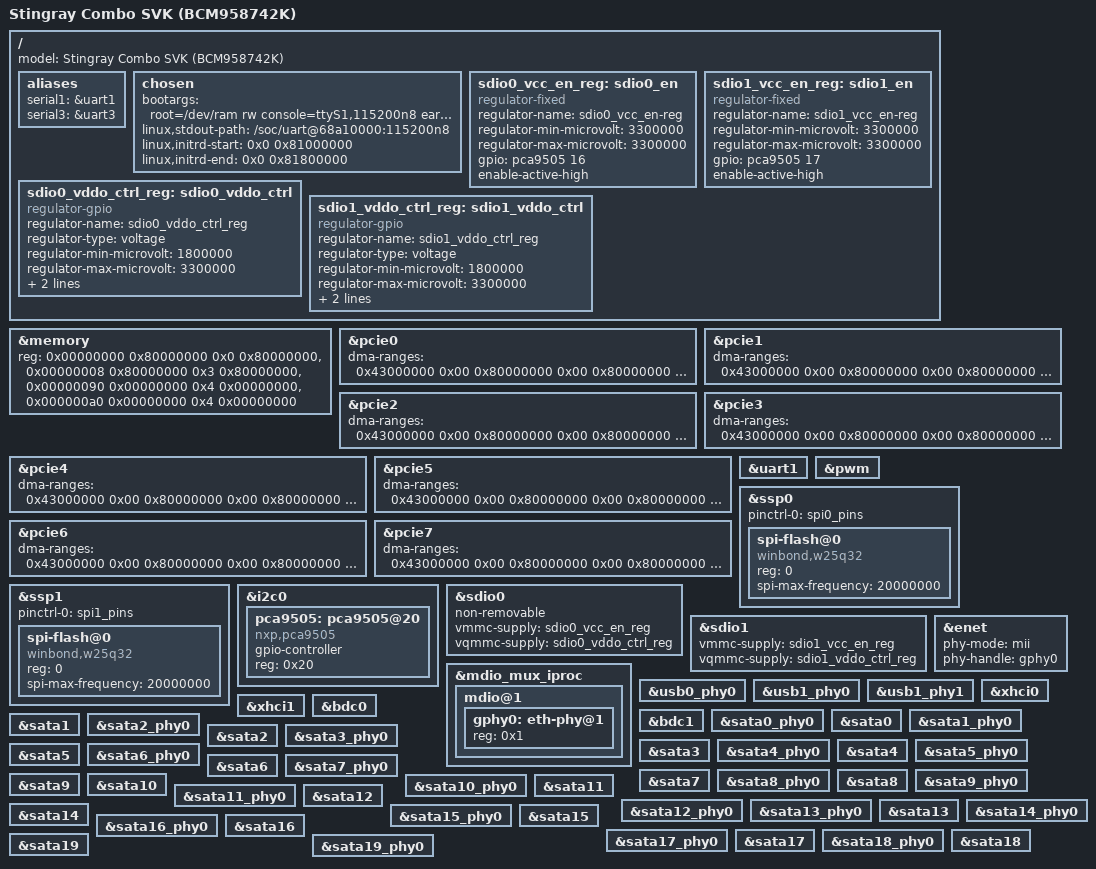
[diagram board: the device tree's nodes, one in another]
/*
 *  BSD LICENSE
 *
 *  Copyright(c) 2016 Broadcom.  All rights reserved.
 *
 *  Redistribution and use in source and binary forms, with or without
 *  modification, are permitted provided that the following conditions
 *  are met:
 *
 *    * Redistributions of source code must retain the above copyright
 *      notice, this list of conditions and the following disclaimer.
 *    * Redistributions in binary form must reproduce the above copyright
 *      notice, this list of conditions and the following disclaimer in
 *      the documentation and/or other materials provided with the
 *      distribution.
 *    * Neither the name of Broadcom Corporation nor the names of its
 *      contributors may be used to endorse or promote products derived
 *      from this software without specific prior written permission.
 *
 *  THIS SOFTWARE IS PROVIDED BY THE COPYRIGHT HOLDERS AND CONTRIBUTORS
 *  "AS IS" AND ANY EXPRESS OR IMPLIED WARRANTIES, INCLUDING, BUT NOT
 *  LIMITED TO, THE IMPLIED WARRANTIES OF MERCHANTABILITY AND FITNESS FOR
 *  A PARTICULAR PURPOSE ARE DISCLAIMED. IN NO EVENT SHALL THE COPYRIGHT
 *  OWNER OR CONTRIBUTORS BE LIABLE FOR ANY DIRECT, INDIRECT, INCIDENTAL,
 *  SPECIAL, EXEMPLARY, OR CONSEQUENTIAL DAMAGES (INCLUDING, BUT NOT
 *  LIMITED TO, PROCUREMENT OF SUBSTITUTE GOODS OR SERVICES; LOSS OF USE,
 *  DATA, OR PROFITS; OR BUSINESS INTERRUPTION) HOWEVER CAUSED AND ON ANY
 *  THEORY OF LIABILITY, WHETHER IN CONTRACT, STRICT LIABILITY, OR TORT
 *  (INCLUDING NEGLIGENCE OR OTHERWISE) ARISING IN ANY WAY OUT OF THE USE
 * OF THIS SOFTWARE, EVEN IF ADVISED OF THE POSSIBILITY OF SUCH DAMAGE.
 */

/dts-v1/;

/* HACK: Reserve bl31 location
 * The memreserve entry for bl31 is supposed to
 * be updated in DTB by bootloader before handing
 * over DTB to Linux kernel. This is so because
 * only firmware (or bootloader) know the correct
 * location of bl31 and bl31 location in DDR can
 * also change in-future.
 */
/memreserve/ 0x8f000000 0x00100000;

#include "stingray.dtsi"
#include <dt-bindings/gpio/gpio.h>

/ {
	model = "Stingray Combo SVK (BCM958742K)";

	aliases {
		serial1 = &uart1;
		serial3 = &uart3;
	};

	chosen { /* HACK: hard-code kernel args and initrd location */
		bootargs = "root=/dev/ram rw console=ttyS1,115200n8 \
			    earlycon=uart8250,mmio32,0x68a10000 cma=64M";
		linux,stdout-path = "/soc/uart@68a10000:115200n8";
		linux,initrd-start = <0x0 0x81000000>;
		linux,initrd-end = <0x0 0x81800000>;
	};

	sdio0_vcc_en_reg: sdio0_en {
		compatible = "regulator-fixed";
		regulator-name = "sdio0_vcc_en-reg";
		regulator-min-microvolt = <3300000>;
		regulator-max-microvolt = <3300000>;
		gpio = <&pca9505 16 0>;
		enable-active-high;
	};

	sdio1_vcc_en_reg: sdio1_en {
		compatible = "regulator-fixed";
		regulator-name = "sdio1_vcc_en-reg";
		regulator-min-microvolt = <3300000>;
		regulator-max-microvolt = <3300000>;
		gpio = <&pca9505 17 0>;
		enable-active-high;
	};

	sdio0_vddo_ctrl_reg: sdio0_vddo_ctrl {
		compatible = "regulator-gpio";
		regulator-name = "sdio0_vddo_ctrl_reg";
		regulator-type = "voltage";
		regulator-min-microvolt = <1800000>;
		regulator-max-microvolt = <3300000>;
		gpios = <&pca9505 18 0>;
		states = <3300000 0x0
			  1800000 0x1>;
	};

	sdio1_vddo_ctrl_reg: sdio1_vddo_ctrl {
		compatible = "regulator-gpio";
		regulator-name = "sdio1_vddo_ctrl_reg";
		regulator-type = "voltage";
		regulator-min-microvolt = <1800000>;
		regulator-max-microvolt = <3300000>;
		gpios = <&pca9505 19 0>;
		states = <3300000 0x0
			  1800000 0x1>;
	};
};

&memory {
	reg = <0x00000000 0x80000000 0x0 0x80000000>, /* 2G @ 2G */
	      <0x00000008 0x80000000 0x3 0x80000000>, /* 14G @ 34G */
	      <0x00000090 0x00000000 0x4 0x00000000>, /* 16G @ 576G */
	      <0x000000a0 0x00000000 0x4 0x00000000>; /* 16G @ 640G */
};

&pcie0 {
	dma-ranges = <0x43000000 0x00 0x80000000 0x00 0x80000000 0x00 0x80000000
		      0x43000000 0x08 0x00000000 0x08 0x00000000 0x08 0x00000000
		      0x43000000 0x80 0x00000000 0x80 0x00000000 0x40 0x00000000>;

	status = "ok";
};

&pcie1 {
	dma-ranges = <0x43000000 0x00 0x80000000 0x00 0x80000000 0x00 0x80000000
		      0x43000000 0x08 0x00000000 0x08 0x00000000 0x08 0x00000000
		      0x43000000 0x80 0x00000000 0x80 0x00000000 0x40 0x00000000>;

	status = "ok";
};

&pcie2 {
	dma-ranges = <0x43000000 0x00 0x80000000 0x00 0x80000000 0x00 0x80000000
		      0x43000000 0x08 0x00000000 0x08 0x00000000 0x08 0x00000000
		      0x43000000 0x80 0x00000000 0x80 0x00000000 0x40 0x00000000>;

	status = "ok";
};

&pcie3 {
	dma-ranges = <0x43000000 0x00 0x80000000 0x00 0x80000000 0x00 0x80000000
		      0x43000000 0x08 0x00000000 0x08 0x00000000 0x08 0x00000000
		      0x43000000 0x80 0x00000000 0x80 0x00000000 0x40 0x00000000>;

	status = "ok";
};

&pcie4 {
	dma-ranges = <0x43000000 0x00 0x80000000 0x00 0x80000000 0x00 0x80000000
		      0x43000000 0x08 0x00000000 0x08 0x00000000 0x08 0x00000000
		      0x43000000 0x80 0x00000000 0x80 0x00000000 0x40 0x00000000>;

	status = "ok";
};

&pcie5 {
	dma-ranges = <0x43000000 0x00 0x80000000 0x00 0x80000000 0x00 0x80000000
		      0x43000000 0x08 0x00000000 0x08 0x00000000 0x08 0x00000000
		      0x43000000 0x80 0x00000000 0x80 0x00000000 0x40 0x00000000>;

	status = "ok";
};

&pcie6 {
	dma-ranges = <0x43000000 0x00 0x80000000 0x00 0x80000000 0x00 0x80000000
		      0x43000000 0x08 0x00000000 0x08 0x00000000 0x08 0x00000000
		      0x43000000 0x80 0x00000000 0x80 0x00000000 0x40 0x00000000>;

	status = "ok";
};

&pcie7 {
	dma-ranges = <0x43000000 0x00 0x80000000 0x00 0x80000000 0x00 0x80000000
		      0x43000000 0x08 0x00000000 0x08 0x00000000 0x08 0x00000000
		      0x43000000 0x80 0x00000000 0x80 0x00000000 0x40 0x00000000>;

	status = "ok";
};

&uart1 {
	status = "ok";
};

&pwm {
	status = "ok";
};

&ssp0 {
	status = "ok";
	pinctrl-0 = <&spi0_pins>;
	spi-flash@0 {
		compatible = "winbond,w25q32";
		reg = <0>;
		spi-max-frequency = <20000000>;
	};
};

&ssp1 {
	status = "ok";
	pinctrl-0 = <&spi1_pins>;
	spi-flash@0 {
		compatible = "winbond,w25q32";
		reg = <0>;
		spi-max-frequency = <20000000>;
	};
};

&i2c0 {
	status = "ok";
	pca9505: pca9505@20 {
		compatible = "nxp,pca9505";
		gpio-controller;
		#gpio-cells = <2>;
		reg = <0x20>;
	};
};

&sdio0 {
	non-removable;
	status = "ok";
	vmmc-supply = <&sdio0_vcc_en_reg>;
	vqmmc-supply = <&sdio0_vddo_ctrl_reg>;
};

&sdio1 {
	status = "ok";
	vmmc-supply = <&sdio1_vcc_en_reg>;
	vqmmc-supply = <&sdio1_vddo_ctrl_reg>;
};

&mdio_mux_iproc {
	mdio@1 {
		gphy0: eth-phy@1 {
			reg = <0x1>;
		};
	};
};

&enet {
	phy-mode = "mii";
	phy-handle = <&gphy0>;
};

&usb0_phy0 {
	status = "ok";
};

&usb1_phy0 {
	status = "ok";
};

&usb1_phy1 {
	status = "ok";
};

&xhci0 {
	status = "ok";
};

&xhci1 {
	status = "ok";
};

&bdc0 {
	status = "ok";
};

&bdc1 {
	status = "ok";
};

&sata0_phy0 {
	status = "ok";
};

&sata0 {
	status = "ok";
};

&sata1_phy0 {
	status = "ok";
};

&sata1 {
	status = "ok";
};

&sata2_phy0 {
	status = "ok";
};

&sata2 {
	status = "ok";
};

&sata3_phy0 {
	status = "ok";
};

&sata3 {
	status = "ok";
};

&sata4_phy0 {
	status = "ok";
};

&sata4 {
	status = "ok";
};

&sata5_phy0 {
	status = "ok";
};

&sata5 {
	status = "ok";
};

&sata6_phy0 {
	status = "ok";
};

&sata6 {
	status = "ok";
};

&sata7_phy0 {
	status = "ok";
};

&sata7 {
	status = "ok";
};

&sata8_phy0 {
	status = "ok";
};

&sata8 {
	status = "ok";
};

&sata9_phy0 {
	status = "ok";
};

&sata9 {
	status = "ok";
};

&sata10_phy0 {
	status = "ok";
};

&sata10 {
	status = "ok";
};

&sata11_phy0 {
	status = "ok";
};

&sata11 {
	status = "ok";
};

&sata12_phy0 {
	status = "ok";
};

&sata12 {
	status = "ok";
};

&sata13_phy0 {
	status = "ok";
};

&sata13 {
	status = "ok";
};

&sata14_phy0 {
	status = "ok";
};

&sata14 {
	status = "ok";
};

&sata15_phy0 {
	status = "ok";
};

&sata15 {
	status = "ok";
};

&sata16_phy0 {
	status = "ok";
};

&sata16 {
	status = "ok";
};

&sata17_phy0 {
	status = "ok";
};

&sata17 {
	status = "ok";
};

&sata18_phy0 {
	status = "ok";
};

&sata18 {
	status = "ok";
};

&sata19_phy0 {
	status = "ok";
};

&sata19 {
	status = "ok";
};
